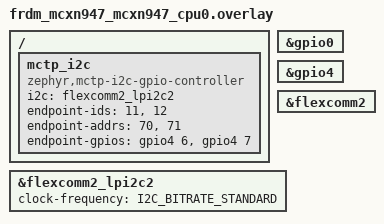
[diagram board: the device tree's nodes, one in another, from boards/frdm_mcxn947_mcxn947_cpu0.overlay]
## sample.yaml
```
sample:
  name: MCTP I2C+GPIO Bus Owner
common:
  tags:
    - pmci
    - mctp
tests:
  sample.pmci.mctp.i2c_gpio_bus_owner:
    platform_allow:
      - frdm_mcxn947/mcxn947/cpu0
    harness: console
    harness_config:
      type: multi_line
      regex:
        - "(.*)MCTP Host EID: (.*) on (.*)"
        - "(.*)received message (.*) from endpoint (.*)"
```

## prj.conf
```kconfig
CONFIG_I2C=y
CONFIG_I2C_RTIO=y
CONFIG_MCTP=y
CONFIG_MCTP_I2C_GPIO_CONTROLLER=y
CONFIG_LOG=y
CONFIG_LOG_BUFFER_SIZE=4096
```

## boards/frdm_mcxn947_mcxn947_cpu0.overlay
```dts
#include <zephyr/dt-bindings/gpio/gpio.h>

/* Sets up I2C and a GPIO on JP8 to use as our i2c bus for MCTP */

&gpio0 {
	status = "okay";
};

&gpio4 {
	status = "okay";
};

&flexcomm2 {
	status = "okay";
};

&flexcomm2_lpi2c2 {
	status = "okay";
	clock-frequency = <I2C_BITRATE_STANDARD>;
};

/ {
	mctp_i2c: mctp_i2c {
		compatible = "zephyr,mctp-i2c-gpio-controller";
		i2c = <&flexcomm2_lpi2c2>;
		endpoint-ids = <11>, <12>;
		endpoint-addrs = <70>, <71>;
		endpoint-gpios = <&gpio4 6 GPIO_ACTIVE_HIGH>, <&gpio4 7 GPIO_ACTIVE_HIGH>;
	};
};
```

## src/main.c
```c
/*
 * Copyright (c) 2025 Intel Corporation
 *
 * SPDX-License-Identifier: Apache-2.0
 */

#include <stdio.h>
#include <assert.h>
#include <zephyr/types.h>
#include <zephyr/kernel.h>
#include <libmctp.h>
#include <zephyr/pmci/mctp/mctp_i2c_gpio_controller.h>

#include <zephyr/logging/log.h>
LOG_MODULE_REGISTER(mctp_i2c_gpio_bus_owner);

#define LOCAL_EID 20

MCTP_I2C_GPIO_CONTROLLER_DT_DEFINE(mctp_i2c_ctrl, DT_NODELABEL(mctp_i2c));

static void rx_message(uint8_t eid, bool tag_owner, uint8_t msg_tag, void *data, void *msg,
		       size_t len)
{
	LOG_INF("received message \"%s\" from endpoint %d to %d, msg_tag %d, len %zu", (char *)msg,
		eid, LOCAL_EID, msg_tag, len);
}

int main(void)
{
	int rc;
	struct mctp *mctp_ctx;

	LOG_INF("MCTP Host EID:%d on %s\n", LOCAL_EID, CONFIG_BOARD_TARGET);

	mctp_ctx = mctp_init();
	__ASSERT_NO_MSG(mctp_ctx != NULL);
	mctp_register_bus(mctp_ctx, &mctp_i2c_ctrl.binding, LOCAL_EID);
	mctp_set_rx_all(mctp_ctx, rx_message, NULL);

	while (true) {
		for (int i = 0; i < mctp_i2c_ctrl.num_endpoints; i++) {

			LOG_INF("sending message \"ping\" to endpoint %d",
				mctp_i2c_ctrl.endpoint_ids[i]);
			rc = mctp_message_tx(mctp_ctx, mctp_i2c_ctrl.endpoint_ids[i], false,
					0, "ping", sizeof("ping"));
			if (rc != 0) {
				LOG_WRN("Failed to send message \"ping\" to endpoint %d,"
					" errno %d\n", mctp_i2c_ctrl.endpoint_ids[i], rc);
			}

			k_msleep(1000);
		}
	}

	return 0;
}
```
